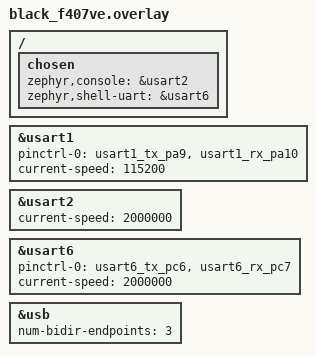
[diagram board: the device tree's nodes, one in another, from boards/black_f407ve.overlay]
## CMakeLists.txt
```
cmake_minimum_required(VERSION 3.20.0)

find_package(Zephyr REQUIRED HINTS $ENV{ZEPHYR_BASE})

project(js2232)

target_sources(app PRIVATE src/main.cpp src/usb-loopback.cpp)
```

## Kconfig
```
config JS2232_BULK_EP_MPS
	int
	depends on USB_DEVICE_STACK
	default 512 if USB_DC_HAS_HS_SUPPORT
	default 64
	help
	  js2232 bulk endpoint size

config JS2232_BCDDEVICE
	int
	depends on USB_DEVICE_STACK
	default 1792
	help
	  js2232 bcdDevice

source "Kconfig.zephyr"
```

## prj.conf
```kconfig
CONFIG_GPIO=y
CONFIG_PICOLIBC=y

# USB
CONFIG_USB_DEVICE_STACK=y
CONFIG_USB_DEVICE_VID=0x0403
CONFIG_USB_DEVICE_PID=0x6010
CONFIG_USB_DEVICE_MANUFACTURER="Pyongyang Chewing Gum Factory"
CONFIG_USB_DEVICE_PRODUCT="js2232"
CONFIG_USB_DEVICE_CUSTOM_COMMON_DESCRIPTOR=y
CONFIG_USB_DEVICE_CUSTOM_ENDPOINT_CONFIG=y
# not relevant with custom common desc.
CONFIG_USB_SELF_POWERED=n
CONFIG_USB_MAX_ALT_SETTING=1
CONFIG_USB_REQUEST_BUFFER_SIZE=8
# not releveant with no xfer api
CONFIG_USB_MAX_NUM_TRANSFERS=1
CONFIG_USB_NUMOF_EP_WRITE_RETRIES=0
CONFIG_USB_DC_STM32_DBL_BUF=y
CONFIG_USB_TRANSFER_API=n

# UART
CONFIG_UART_ASYNC_API=y
CONFIG_UART_INTERRUPT_DRIVEN=n

# SPI
# TODO

# debug
CONFIG_ASSERT=n
CONFIG_DEBUG=n
CONFIG_COMPILER_OPT="-gdwarf-5 -save-temps"

# console
# CONFIG_CONSOLE=n
# CONFIG_UART_CONSOLE=n

# logging
CONFIG_LOG=y
CONFIG_LOG_PRINTK=y
# CONFIG_LOG_SPEED=y
# CONFIG_LOG_BUFFER_SIZE=4096
CONFIG_LOG_FRONTEND=y
CONFIG_LOG_FRONTEND_ONLY=y
# CONFIG_LOG_MEM_UTILIZATION=y
CONFIG_LOG_FRONTEND_DICT_UART=y
# CONFIG_LOG_BACKEND_UART=y
# CONFIG_LOG_BACKEND_UART_ASYNC=y
# CONFIG_LOG_BACKEND_UART_OUTPUT_DICTIONARY_BIN=y
# CONFIG_LOG_BACKEND_UART_OUTPUT_DICTIONARY=y
# CONFIG_LOG_FMT_SECTION=y
# CONFIG_LOG_FRONTEND_DICT_UART=y
CONFIG_LOG_FRONTEND_DICT_UART_BUFFER_SIZE=4096
CONFIG_USB_DEVICE_LOG_LEVEL_INF=y
# CONFIG_USB_DEVICE_LOG_LEVEL_DBG=y
CONFIG_USB_DEVICE_LOG_LEVEL_INF=y

# perf mon
# CONFIG_SCHED_THREAD_USAGE=y
# CONFIG_THREAD_ANALYZER=y
# CONFIG_THREAD_ANALYZER_USE_LOG=y
# CONFIG_THREAD_ANALYZER_AUTO=y
# CONFIG_THREAD_ANALYZER_AUTO_INTERVAL=10
```

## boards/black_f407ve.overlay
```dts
/ {
	chosen {
		zephyr,console = &usart2;
		zephyr,shell-uart = &usart6;
	};
};

&usart1 {
	pinctrl-0 = <&usart1_tx_pa9 &usart1_rx_pa10>;
	current-speed = <115200>;
};

&usart2 {
	current-speed = <2000000>;
};

&usart6 {
	pinctrl-0 = <&usart6_tx_pc6 &usart6_rx_pc7>;
	pinctrl-names = "default";
	current-speed = <2000000>;
	status = "okay";
};

&usb {
	num-bidir-endpoints = <3>;
};
```

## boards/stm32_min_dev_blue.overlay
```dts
/ {
	chosen {
		zephyr,console = &usart1;
	};
};

&dma1 {
	status = "okay";
};

&usart1 {
	pinctrl-0 = <&usart1_tx_remap1_pb6 &usart1_rx_remap1_pb7>;
	current-speed = <3000000>;
	dmas = <&dma1 4 0x440>, <&dma1 5 0x480>;
	dma-names = "tx", "rx";
};

&usb {
	pinctrl-0 = <&usb_dm_pa11 &usb_dp_pa12>;
	pinctrl-1 = <&usb_dm_pa11_gpio_se0 &usb_dp_pa12_gpio_se0>;
	pinctrl-names = "default", "gpio_se0";
	num-bidir-endpoints = <3>;
};
```

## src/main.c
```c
#include <zephyr/zephyr.h>
#include <zephyr/drivers/gpio.h>

#define SLEEP_TIME_MS   1000

#define LED0_NODE DT_ALIAS(led0)

static const struct gpio_dt_spec led = GPIO_DT_SPEC_GET(LED0_NODE, gpios);

void main(void)
{
	int ret;

	if (!device_is_ready(led.port)) {
		return;
	}

	ret = gpio_pin_configure_dt(&led, GPIO_OUTPUT_ACTIVE);
	if (ret < 0) {
		return;
	}

	while (1) {
		ret = gpio_pin_toggle_dt(&led);
		if (ret < 0) {
			return;
		}
		k_msleep(SLEEP_TIME_MS);
	}
}
```

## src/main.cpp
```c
#include <zephyr/drivers/gpio.h>
#include <zephyr/drivers/pinctrl.h>
#include <zephyr/logging/log.h>
#include <zephyr/usb/usb_device.h>
#include <zephyr/zephyr.h>

LOG_MODULE_REGISTER(main);

#define SLEEP_TIME_MS 1000

#define LED0_NODE DT_ALIAS(led0)
static const struct gpio_dt_spec led = GPIO_DT_SPEC_GET(LED0_NODE, gpios);

int main(void) {
    int ret;

    printk("Hello World! %s\n", CONFIG_BOARD);

    ret = usb_enable(nullptr);
    if (ret != 0) {
        LOG_ERR("Failed to enable USB");
        return -1;
    }

    LOG_INF("entered main.");

    if (!device_is_ready(led.port)) {
        return -1;
    }

    ret = gpio_pin_configure_dt(&led, GPIO_OUTPUT_ACTIVE);
    if (ret < 0) {
        return -1;
    }

    while (1) {
        ret = gpio_pin_toggle_dt(&led);
        if (ret < 0) {
            return -1;
        }
        k_msleep(SLEEP_TIME_MS);
    }

    return -1;
}
```

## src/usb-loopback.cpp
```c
#define __ASSERT_ON 1
#include <sys/__assert.h>
#define assert __ASSERT_NO_MSG

#include <zephyr/init.h>

#include <usb_descriptor.h>
#include <zephyr/sys/byteorder.h>
#include <zephyr/usb/usb_device.h>

#define LOG_LEVEL 4
#include <zephyr/logging/log.h>
LOG_MODULE_REGISTER(js2232_usb);

constexpr int IF0_IN_EP_ADDR  = 0x81;
constexpr int IF0_OUT_EP_ADDR = 0x02;

constexpr int IF0_IN_EP_IDX  = 0;
constexpr int IF0_OUT_EP_IDX = 1;

constexpr uint8_t REQ_SET_TEST_MODE = 0x42;
constexpr uint8_t REQ_SET_PACKET_SZ = 0x43;

enum test_mode_t : uint16_t {
    INVALID_MODE,
    LOOPBACK_BULK,
    OUT_BULK,
    IN_BULK,
};

static test_mode_t test_mode = INVALID_MODE;
static uint16_t test_pkt_sz;

__attribute__((aligned(4))) static uint8_t loopback_buf[4096];
// BUILD_ASSERT(sizeof(loopback_buf) == CONFIG_JS2232_BULK_EP_MPS);

struct usb_loopback_config {
    struct usb_if_descriptor if0;
    struct usb_ep_descriptor if0_in_ep;
    struct usb_ep_descriptor if0_out_ep;
} __packed;

USBD_CLASS_DESCR_DEFINE(primary, 0)
struct usb_loopback_config loopback_cfg = {
    /* Interface descriptor 0 */
    .if0 =
        {
            .bLength            = sizeof(struct usb_if_descriptor),
            .bDescriptorType    = USB_DESC_INTERFACE,
            .bInterfaceNumber   = 0,
            .bAlternateSetting  = 0,
            .bNumEndpoints      = 2,
            .bInterfaceClass    = USB_BCC_VENDOR,
            .bInterfaceSubClass = 0xFF,
            .bInterfaceProtocol = 0xFF,
            .iInterface         = 0,
        },

    /* Data Endpoint IN 1 */
    .if0_in_ep =
        {
            .bLength          = sizeof(struct usb_ep_descriptor),
            .bDescriptorType  = USB_DESC_ENDPOINT,
            .bEndpointAddress = IF0_IN_EP_ADDR,
            .bmAttributes     = USB_DC_EP_BULK,
            .wMaxPacketSize   = sys_cpu_to_le16(CONFIG_JS2232_BULK_EP_MPS),
            .bInterval        = 0x00,
        },

    /* Data Endpoint OUT 1 */
    .if0_out_ep =
        {
            .bLength          = sizeof(struct usb_ep_descriptor),
            .bDescriptorType  = USB_DESC_ENDPOINT,
            .bEndpointAddress = IF0_OUT_EP_ADDR,
            .bmAttributes     = USB_DC_EP_BULK,
            .wMaxPacketSize   = sys_cpu_to_le16(CONFIG_JS2232_BULK_EP_MPS),
            .bInterval        = 0x00,
        },
};

USBD_DEVICE_DESCR_DEFINE(primary)
struct usb_common_descriptor common_desc = {
    /* Device descriptor */
    .device_descriptor =
        {
            .bLength            = sizeof(struct usb_device_descriptor),
            .bDescriptorType    = USB_DESC_DEVICE,
            .bcdUSB             = sys_cpu_to_le16(USB_SRN_2_0),
            .bDeviceClass       = 0,
            .bDeviceSubClass    = 0,
            .bDeviceProtocol    = 0,
            .bMaxPacketSize0    = USB_MAX_CTRL_MPS,
            .idVendor           = sys_cpu_to_le16((uint16_t)CONFIG_USB_DEVICE_VID),
            .idProduct          = sys_cpu_to_le16((uint16_t)CONFIG_USB_DEVICE_PID),
            .bcdDevice          = sys_cpu_to_le16((uint16_t)CONFIG_JS2232_BCDDEVICE),
            .iManufacturer      = 1,
            .iProduct           = 2,
            .iSerialNumber      = 3,
            .bNumConfigurations = 1,
        },
    /* Configuration descriptor */
    .cfg_descr =
        {
            .bLength             = sizeof(struct usb_cfg_descriptor),
            .bDescriptorType     = USB_DESC_CONFIGURATION,
            .wTotalLength        = 0,
            .bNumInterfaces      = 1,
            .bConfigurationValue = 1,
            .iConfiguration      = 0,
            .bmAttributes        = USB_SCD_RESERVED,
            .bMaxPower           = 500 / 2,
        },
};

#pragma GCC push_options
#pragma GCC optimize(2)
static void invert_buf(uint8_t *buf, uint16_t len) {
    uint8_t *p8 = buf;
    while (len && (uintptr_t)p8 & 0b11) {
        *p8 = *p8 ^ 0xff;
        ++p8;
        len -= sizeof(*p8);
    }
    uint32_t *p32 = (uint32_t *)__builtin_assume_aligned(p8, 4);
    while (len >= 4) {
        *p32 = *p32 ^ 0xffffffff;
        ++p32;
        len -= sizeof(*p32);
    }
    p8 = (uint8_t *)__builtin_assume_aligned(p32, 4);
    while (len) {
        *p8 = *p8 ^ 0xff;
        ++p8;
        len -= sizeof(*p8);
    }
}

static void invert_buf_align32(uint8_t *buf, uint32_t len) {
    uint32_t *p32 = (uint32_t *)__builtin_assume_aligned(buf, 4);
    while (len >= 4) {
        *p32 = *p32 ^ 0xffffffff;
        ++p32;
        len -= sizeof(*p32);
    }
}
#pragma GCC pop_options

static void xfer_rx_cb(uint8_t ep, enum usb_dc_ep_cb_status_code status) {
    int res;
    uint32_t ret_bytes;
    switch (test_mode) {
    case LOOPBACK_BULK:
        res = usb_read(IF0_OUT_EP_ADDR, loopback_buf, test_pkt_sz, &ret_bytes);
        // assert(!res && ret_bytes == 64);
        // LOG_INF("rb: %u", ret_bytes);
        if (res || ret_bytes != test_pkt_sz) {
            // LOG_INF("read fail res: %d ret_bytes: %u", res, ret_bytes);
        }
        invert_buf_align32(loopback_buf, test_pkt_sz);
        res = usb_write(IF0_IN_EP_ADDR, loopback_buf, test_pkt_sz, &ret_bytes);
        // assert(res == 0 && ret_bytes == 64);
        if (res || ret_bytes != test_pkt_sz) {
            // LOG_INF("write fail res: %d ret_bytes: %u", res, ret_bytes);
        }
        break;
    case OUT_BULK:
        res = usb_read(IF0_OUT_EP_ADDR, loopback_buf, test_pkt_sz, &ret_bytes);
        // res = usb_read(IF0_OUT_EP_ADDR, nullptr, 0, &ret_bytes);
        LOG_INF("rb: %u", ret_bytes);
        if (res || ret_bytes != test_pkt_sz) {
            // LOG_INF("read fail res: %d ret_bytes: %u", res, ret_bytes);
        }
        break;
    case IN_BULK:
        // assert(!"Invalid test mode");
        break;
    default:
        // assert(!"Invalid test mode");
        break;
    }
}

static void xfer_tx_cb(uint8_t ep, enum usb_dc_ep_cb_status_code status) {
    int res            = -1;
    uint32_t ret_bytes = 0;
    // LOG_INF("tx_cb: ep: 0x%02x status: %d", ep, status);
    switch (test_mode) {
    case LOOPBACK_BULK:
        break;
    case OUT_BULK:
        // assert(!"Invalid test mode");
        break;
    case IN_BULK:
        res = usb_write(IF0_IN_EP_ADDR, loopback_buf, test_pkt_sz, &ret_bytes);
        if (res || ret_bytes != test_pkt_sz) {
            // LOG_INF("write fail res: %d ret_bytes: %u", res, ret_bytes);
        }
        break;
    default:
        // assert(!"Invalid test mode");
        break;
    }
}

static struct usb_ep_cfg_data ep_cfg[] = {
    {
        .ep_cb   = xfer_rx_cb,
        .ep_addr = IF0_OUT_EP_ADDR,
    },
    {
        .ep_cb   = xfer_tx_cb,
        .ep_addr = IF0_IN_EP_ADDR,
    },
};

static void loopback_status_cb(struct usb_cfg_data *cfg, enum usb_dc_status_code status,
                               const uint8_t *param) {
    ARG_UNUSED(cfg);

    LOG_INF("%s: status: %d", __FUNCTION__, status);

    switch (status) {
    case USB_DC_INTERFACE:
        LOG_INF("USB interface configured");
        break;
    case USB_DC_SET_HALT:
        LOG_INF("Set Feature ENDPOINT_HALT");
        break;
    case USB_DC_CLEAR_HALT:
        LOG_INF("Clear Feature ENDPOINT_HALT");
        break;
    case USB_DC_CONFIGURED:
        LOG_INF("Configured");
        break;
    default:
        break;
    }
}

static int loopback_vendor_handler(struct usb_setup_packet *setup, int32_t *len, uint8_t **data) {
    int res            = -1;
    uint32_t ret_bytes = 0;
    LOG_INF("Class request: bRequest 0x%x bmRequestType 0x%x len %d", setup->bRequest,
            setup->bmRequestType, *len);

    if (setup->RequestType.recipient != USB_REQTYPE_RECIPIENT_DEVICE ||
        setup->RequestType.type != USB_REQTYPE_TYPE_VENDOR) {
        return -ENOTSUP;
    }

    if (setup->bRequest == REQ_SET_TEST_MODE) {
        test_mode = (test_mode_t)setup->wValue;
        memset(loopback_buf, 0, sizeof(loopback_buf));
        switch (test_mode) {
        case LOOPBACK_BULK:
            LOG_INF("Test mode: loopback bulk");
            break;
        case OUT_BULK:
            LOG_INF("Test mode: out bulk");
            break;
        case IN_BULK:
            LOG_INF("Test mode: in bulk");
            res = usb_write(IF0_IN_EP_ADDR, loopback_buf, test_pkt_sz, &ret_bytes);
            if (res || ret_bytes != test_pkt_sz) {
                LOG_INF("write fail res: %d ret_bytes: %u", res, ret_bytes);
            }
            break;
        default:
            assert(!"Invalid test mode");
            break;
        }
        return 0;
    } else if (setup->bRequest == REQ_SET_PACKET_SZ) {
        test_pkt_sz = setup->wValue;
        assert(test_pkt_sz <= sizeof(loopback_buf));
        return 0;
    }

    return -ENOTSUP;
}

static void loopback_interface_config(struct usb_desc_header *head, uint8_t bInterfaceNumber) {
    ARG_UNUSED(head);

    LOG_INF("%s: bInterfaceNumber: %d", __PRETTY_FUNCTION__, bInterfaceNumber);
    loopback_cfg.if0.bInterfaceNumber = bInterfaceNumber;
}

USBD_DEFINE_CFG_DATA(loopback_config) = {
    .usb_device_description = nullptr,
    .interface_descriptor   = &loopback_cfg.if0,
    .interface_config       = loopback_interface_config,
    .cb_usb_status          = loopback_status_cb,
    .interface =
        {
            .class_handler  = nullptr,
            .vendor_handler = loopback_vendor_handler,
            .custom_handler = nullptr,
        },
    .num_endpoints = ARRAY_SIZE(ep_cfg),
    .endpoint      = ep_cfg,
};
```

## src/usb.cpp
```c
#include <zephyr/init.h>

#include <usb_descriptor.h>
#include <zephyr/sys/byteorder.h>
#include <zephyr/usb/usb_device.h>

#define LOG_LEVEL 4
#include <zephyr/logging/log.h>
LOG_MODULE_REGISTER(js2232_usb);

#define IF0_IN_EP_ADDR 0x81
#define IF0_OUT_EP_ADDR 0x01

#define IF0_IN_EP_IDX 0
#define IF0_OUT_EP_IDX 1

#define IF1_IN_EP_ADDR 0x82
#define IF1_OUT_EP_ADDR 0x02

#define IF1_IN_EP_IDX 3
#define IF1_OUT_EP_IDX 4

static uint8_t loopback_buf[1024];
BUILD_ASSERT(sizeof(loopback_buf) == CONFIG_USB_REQUEST_BUFFER_SIZE);

struct usb_loopback_config {
    struct usb_if_descriptor if0;
    struct usb_ep_descriptor if0_in_ep;
    struct usb_ep_descriptor if0_out_ep;
    // struct usb_if_descriptor if1;
    // struct usb_ep_descriptor if1_in_ep;
    // struct usb_ep_descriptor if1_out_ep;
} __packed;

USBD_CLASS_DESCR_DEFINE(primary, 0)
struct usb_loopback_config loopback_cfg = {
    /* Interface descriptor 0 */
    .if0 =
        {
            .bLength            = sizeof(struct usb_if_descriptor),
            .bDescriptorType    = USB_DESC_INTERFACE,
            .bInterfaceNumber   = 0,
            .bAlternateSetting  = 0,
            .bNumEndpoints      = 2,
            .bInterfaceClass    = USB_BCC_VENDOR,
            .bInterfaceSubClass = 0xFF,
            .bInterfaceProtocol = 0xFF,
            .iInterface         = 0,
        },

    /* Data Endpoint IN 1 */
    .if0_in_ep =
        {
            .bLength          = sizeof(struct usb_ep_descriptor),
            .bDescriptorType  = USB_DESC_ENDPOINT,
            .bEndpointAddress = IF0_IN_EP_ADDR,
            .bmAttributes     = USB_DC_EP_BULK,
            .wMaxPacketSize   = sys_cpu_to_le16(CONFIG_JS2232_BULK_EP_MPS),
            .bInterval        = 0x00,
        },

    /* Data Endpoint OUT 1 */
    .if0_out_ep =
        {
            .bLength          = sizeof(struct usb_ep_descriptor),
            .bDescriptorType  = USB_DESC_ENDPOINT,
            .bEndpointAddress = IF0_OUT_EP_ADDR,
            .bmAttributes     = USB_DC_EP_BULK,
            .wMaxPacketSize   = sys_cpu_to_le16(CONFIG_JS2232_BULK_EP_MPS),
            .bInterval        = 0x00,
        },

    // /* Interface descriptor 1 */
    // .if1 =
    //     {
    //         .bLength            = sizeof(struct usb_if_descriptor),
    //         .bDescriptorType    = USB_DESC_INTERFACE,
    //         .bInterfaceNumber   = 1,
    //         .bAlternateSetting  = 0,
    //         .bNumEndpoints      = 2,
    //         .bInterfaceClass    = USB_BCC_VENDOR,
    //         .bInterfaceSubClass = 0xFF,
    //         .bInterfaceProtocol = 0xFF,
    //         .iInterface         = 0,
    //     },

    // /* Data Endpoint IN 2 */
    // .if1_in_ep =
    //     {
    //         .bLength          = sizeof(struct usb_ep_descriptor),
    //         .bDescriptorType  = USB_DESC_ENDPOINT,
    //         .bEndpointAddress = IF1_IN_EP_ADDR,
    //         .bmAttributes     = USB_DC_EP_BULK,
    //         .wMaxPacketSize   = sys_cpu_to_le16(CONFIG_JS2232_BULK_EP_MPS),
    //         .bInterval        = 0x00,
    //     },

    // /* Data Endpoint OUT 2 */
    // .if1_out_ep =
    //     {
    //         .bLength          = sizeof(struct usb_ep_descriptor),
    //         .bDescriptorType  = USB_DESC_ENDPOINT,
    //         .bEndpointAddress = IF1_OUT_EP_ADDR,
    //         .bmAttributes     = USB_DC_EP_BULK,
    //         .wMaxPacketSize   = sys_cpu_to_le16(CONFIG_JS2232_BULK_EP_MPS),
    //         .bInterval        = 0x00,
    //     },
};

USBD_DEVICE_DESCR_DEFINE(primary)
struct usb_common_descriptor common_desc = {
    /* Device descriptor */
    .device_descriptor =
        {
            .bLength            = sizeof(struct usb_device_descriptor),
            .bDescriptorType    = USB_DESC_DEVICE,
            .bcdUSB             = sys_cpu_to_le16(USB_SRN_2_0),
            .bDeviceClass       = 0,
            .bDeviceSubClass    = 0,
            .bDeviceProtocol    = 0,
            .bMaxPacketSize0    = USB_MAX_CTRL_MPS,
            .idVendor           = sys_cpu_to_le16((uint16_t)CONFIG_USB_DEVICE_VID),
            .idProduct          = sys_cpu_to_le16((uint16_t)CONFIG_USB_DEVICE_PID),
            .bcdDevice          = sys_cpu_to_le16((uint16_t)CONFIG_JS2232_BCDDEVICE),
            .iManufacturer      = 1,
            .iProduct           = 2,
            .iSerialNumber      = 3,
            .bNumConfigurations = 1,
        },
    /* Configuration descriptor */
    .cfg_descr =
        {
            .bLength             = sizeof(struct usb_cfg_descriptor),
            .bDescriptorType     = USB_DESC_CONFIGURATION,
            .wTotalLength        = 0,
            .bNumInterfaces      = 1,
            .bConfigurationValue = 1,
            .iConfiguration      = 0,
            .bmAttributes        = USB_SCD_RESERVED,
            .bMaxPower           = 500 / 2,
        },
};

static void loopback_out_cb(uint8_t ep, enum usb_dc_ep_cb_status_code ep_status) {
    uint32_t bytes_to_read;

    usb_read(ep, nullptr, 0, &bytes_to_read);
    LOG_INF("ep 0x%x, bytes to read %d ", ep, bytes_to_read);
    usb_read(ep, loopback_buf, bytes_to_read, nullptr);
    LOG_HEXDUMP_INF(loopback_buf, bytes_to_read, "out ep read: ");
    if (usb_write(ep | 0x80, loopback_buf, bytes_to_read, nullptr)) {
        LOG_INF("wtf ep 0x%x", ep);
    }
}

static void loopback_in_cb(uint8_t ep, enum usb_dc_ep_cb_status_code ep_status) {
    LOG_INF("%s try ep 0x%x", __FUNCTION__, ep);
    if (usb_write(ep, loopback_buf, 4, nullptr)) {
        LOG_INF("ep 0x%x", ep);
    }
}

static struct usb_ep_cfg_data ep_cfg[] = {
    {
        .ep_cb   = loopback_out_cb,
        .ep_addr = IF0_OUT_EP_ADDR,
    },
    {
        .ep_cb   = loopback_in_cb,
        .ep_addr = IF0_IN_EP_ADDR,
    },
    // {
    //     .ep_cb   = nullptr,
    //     .ep_addr = IF1_OUT_EP_ADDR,
    // },
    // {
    //     .ep_cb   = nullptr,
    //     .ep_addr = IF1_IN_EP_ADDR,
    // },
};

static void loopback_status_cb(struct usb_cfg_data *cfg, enum usb_dc_status_code status,
                               const uint8_t *param) {
    ARG_UNUSED(cfg);

    LOG_INF("%s: status: %d", __FUNCTION__, status);

    switch (status) {
    case USB_DC_INTERFACE:
        loopback_in_cb(ep_cfg[IF0_IN_EP_IDX].ep_addr, USB_DC_EP_SETUP);
        LOG_INF("USB interface configured");
        break;
    case USB_DC_SET_HALT:
        LOG_INF("Set Feature ENDPOINT_HALT");
        break;
    case USB_DC_CLEAR_HALT:
        LOG_INF("Clear Feature ENDPOINT_HALT");
        if (*param == ep_cfg[IF0_IN_EP_IDX].ep_addr) {
            loopback_in_cb(ep_cfg[IF0_IN_EP_IDX].ep_addr, USB_DC_EP_SETUP);
        }
        break;
    default:
        break;
    }
}

static int loopback_vendor_handler(struct usb_setup_packet *setup, int32_t *len, uint8_t **data) {
    LOG_INF("Class request: bRequest 0x%x bmRequestType 0x%x len %d", setup->bRequest,
            setup->bmRequestType, *len);

    if (setup->RequestType.recipient != USB_REQTYPE_RECIPIENT_DEVICE) {
        return -ENOTSUP;
    }

    if (usb_reqtype_is_to_device(setup) && setup->bRequest == 0x5b) {
        LOG_INF("Host-to-Device, data %p", *data);
        /*
         * Copy request data in loopback_buf buffer and reuse
         * it later in control device-to-host transfer.
         */
        memcpy(loopback_buf, *data, MIN(sizeof(loopback_buf), setup->wLength));
        return 0;
    }

    if ((usb_reqtype_is_to_host(setup)) && (setup->bRequest == 0x5c)) {
        LOG_INF("Device-to-Host, wLength %d, data %p", setup->wLength, *data);
        *data = loopback_buf;
        *len  = MIN(sizeof(loopback_buf), setup->wLength);
        return 0;
    }

    return -ENOTSUP;
}

static void loopback_interface_config(struct usb_desc_header *head, uint8_t bInterfaceNumber) {
    ARG_UNUSED(head);

    LOG_INF("%s: bInterfaceNumber: %d", __PRETTY_FUNCTION__, bInterfaceNumber);
    loopback_cfg.if0.bInterfaceNumber = bInterfaceNumber;
}

USBD_DEFINE_CFG_DATA(loopback_config) = {
    .usb_device_description = nullptr,
    .interface_descriptor   = &loopback_cfg.if0,
    .interface_config       = loopback_interface_config,
    .cb_usb_status          = loopback_status_cb,
    .interface =
        {
            .class_handler  = nullptr,
            .vendor_handler = loopback_vendor_handler,
            .custom_handler = nullptr,
        },
    .num_endpoints = ARRAY_SIZE(ep_cfg),
    .endpoint      = ep_cfg,
};
```
